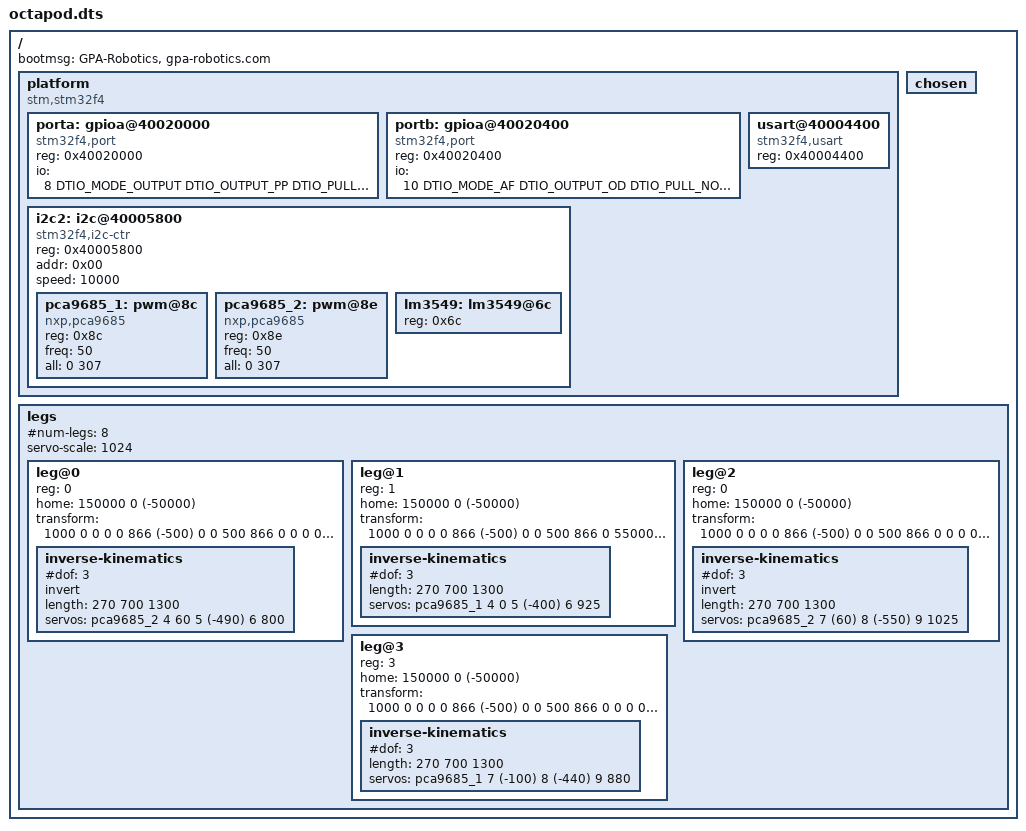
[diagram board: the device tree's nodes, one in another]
/dts-v1/;

#include "platforms/gpio.dtsi"

/ {
    /* Boot message displayed on LCD */
    bootmsg = "GPA-Robotics","gpa-robotics.com";
    #address-cells = <1>;
    #size-cells = <0>;

    platform {
        compatible = "stm,stm32f4";

        #address-cells = <1>;
        #size-cells = <0>;

        porta: gpioa@40020000 {
            compatible = "stm32f4,port";

            /* Address of GPIOA */
            reg = < 0x40020000 >;

            /* IO config */
            io = <
                /* JETSON BATTOC */
                8 DTIO_MODE_OUTPUT DTIO_OUTPUT_PP DTIO_PULL_NONE DTIO_HIGH //PA8 OUT => NVM_BATTOC
            >;
        };

        portb: gpioa@40020400 {
            compatible = "stm32f4,port";

            /* Address of GPIOA */
            reg = < 0x40020400 >;

            /* IO config */
            io = <
                /* IO pin, mode, output type, pull, af(if applicable)*/
                /* I2C2 SDA & SCL */
                10 DTIO_MODE_AF DTIO_OUTPUT_OD DTIO_PULL_NONE DTIO_AF4 //PB10 AF4 => I2C2 SCL
                11 DTIO_MODE_AF DTIO_OUTPUT_OD DTIO_PULL_NONE DTIO_AF4 //PB11 AF4 => I2C2 SDA

                /* TIM4 CH2-4*/
                7 DTIO_MODE_AF DTIO_OUTPUT_PP DTIO_PULL_NONE DTIO_AF1 //PB7 AF1 => TIM4 CH2
                8 DTIO_MODE_AF DTIO_OUTPUT_PP DTIO_PULL_NONE DTIO_AF1 //PB8 AF1 => TIM4 CH3
                9 DTIO_MODE_AF DTIO_OUTPUT_PP DTIO_PULL_NONE DTIO_AF1 //PB9 AF1 => TIM4 CH4
            >;
        };

        i2c2: i2c@40005800 {
            compatible = "stm32f4,i2c-ctr";

            /* Address of I2C2*/
            reg = < 0x40005800 >;

            /* Own I2C address */
            addr = < 0x00 >;

            /* Speed */
            speed = < 10000 >;

            /* Sub devices */
            #address-cells = <1>;
            #size-cells = <0>;

            /* Right */
            pca9685_1: pwm@8c {
                compatible = "nxp,pca9685";
                reg = < 0x8c >;

                /* 50 Hz update frequency*/
                freq = < 50 >;

                /* Default to 307/4096 duty @ 50Hz ~ 1.5ms pulse */
                all = < 0 307 >;
            };

            /* Left */
            pca9685_2: pwm@8e {

                compatible = "nxp,pca9685";

                /* I2C address*/
                reg = < 0x8e >;

                /* 50 Hz update frequency*/
                freq = < 50 >;

                /* Default to 307/4096 duty @ 50Hz ~ 1.5ms pulse */
                all = < 0 307 >;
            };

            lm3549: lm3549@6c {
                reg = < 0x6c >;

            };

        };

        /* USART2 */
        usart@40004400 {
            compatible = "stm32f4,usart";

            reg = < 0x40004400 >;



        };

    };

    /* The 'chosen' node is used to communicate between firmware and board configuration*/
    chosen {


    };

    legs {

        /*Number of legs*/
        #num-legs = < 8 >;
        #address-cells = <1>;
        #size-cells = <0>;

        /* 90 degrees pulse width in us */
        servo-scale = < 1024 >;


        leg@0 {
            /* Index of leg */
            reg = < 0 >;

            /* Home coordinates (leg local-space) */
            home = < 150000 0 (-50000) >;

            /* Matrix used to transform to leg local-space, scaled by 1000 */
            transform = <
                1000    0       0       0
                0       866     (-500)  0
                0       500     866     0
                0       0       0       1000
            >;

            /* IK info */
            inverse-kinematics {
                /* IK driver */
                #dof = < 3 >;

                /* All servos are inverted on this leg*/
                invert; //= < 1 1 1 >;

                /* Length in mm*10 */
                length = < 270 700 1300 >;

                /* Servo indices and offsets*/
                servos = < &pca9685_2
                    4 60
                    5 (-490)
                    6 800
                >;
                //test = < 0 (-900) 900 >;

            };
        };

        leg@1 {
            /* Index of leg */
            reg = < 1 >;

            /* Home coordinates (leg local-space) */
            home = < 150000 0 (-50000) >;

            /* Matrix used to transform to leg local-space, scaled by 1000 */
            transform = <
                1000    0       0       0
                0       866     (-500)  0
                0       500     866     0
                55000   150000  0       1000
            >;

            /* IK info */
            inverse-kinematics {
                /* IK driver */
                #dof = < 3 >;

                /* Length in mm*10 */
                length = < 270 700 1300 >;

                /* Servo indices and offsets*/
                servos = < &pca9685_1
                    4 0
                    5 (-400)
                    6 925
                >;
                //test = < 0 (-900) 900 >;

            };


        };

        leg@2 {
            /* Index of leg */
            reg = < 0 >;

            /* Home coordinates (leg local-space) */
            home = < 150000 0 (-50000) >;

            /* Matrix used to transform to leg local-space, scaled by 1000 */
            transform = <
                1000    0       0       0
                0       866     (-500)  0
                0       500     866     0
                0       0       0       1000
            >;

            /* IK info */
            inverse-kinematics {
                /* IK driver */
                #dof = < 3 >;

                /* All servos are inverted on this leg*/
                invert; //= < 1 1 1 >;

                /* Length in mm*10 */
                length = < 270 700 1300 >;

                /* Servo indices and offsets*/
                servos = < &pca9685_2
                    7 (60)
                    8 (-550)
                    9 1025
                >;
                //test = < 0 (-900) 900 >;

            };
        };

        leg@3 {
            /* Index of leg */
            reg = < 3 >;

            /* Home coordinates (leg local-space) */
            home = < 150000 0 (-50000) >;

            /* Matrix used to transform to leg local-space, scaled by 1000 */
            transform = <
                1000    0       0       0
                0       866     (-500)  0
                0       500     866     0
                0       0       0       1000
            >;

            /* IK info */
            inverse-kinematics {
                /* IK driver */
                #dof = < 3 >;

                /* Length in mm*10 */
                length = < 270 700 1300 >;

                /* Servo indices and offsets*/
                servos = < &pca9685_1
                    7 (-100)
                    8 (-440)
                    9 880
                >;
                //test = < 0 (-900) 900 >;

            };
        };

    };
};



